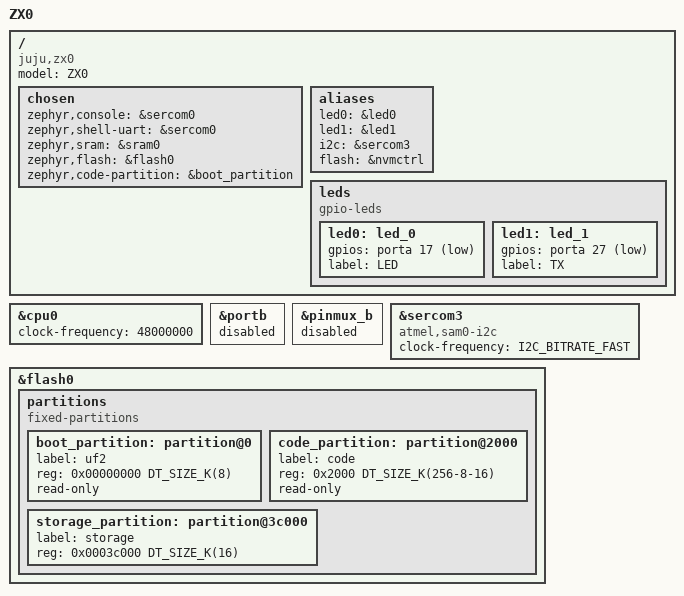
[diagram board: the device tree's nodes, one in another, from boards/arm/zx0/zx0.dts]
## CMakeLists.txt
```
cmake_minimum_required(VERSION 3.13.1)

list(APPEND BOARD_ROOT ${CMAKE_CURRENT_SOURCE_DIR})
set(BOARD zx0)

find_package(Zephyr REQUIRED HINTS $ENV{ZEPHYR_BASE})
project(zx0-boot)

target_sources(app PRIVATE src/main.cpp)
```

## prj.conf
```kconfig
# Drivers and peripherals
CONFIG_I2C=n
CONFIG_WATCHDOG=n
CONFIG_GPIO=y
CONFIG_PINMUX=y
CONFIG_SPI=n
CONFIG_SERIAL=n
CONFIG_FLASH=y
CONFIG_SAM0_EIC=n
CONFIG_SOC_FLASH_SAM0=y

# Power management
CONFIG_PM=n

# Interrupts
CONFIG_DYNAMIC_INTERRUPTS=n
CONFIG_IRQ_OFFLOAD=n

# Memory protection
CONFIG_THREAD_STACK_INFO=n
CONFIG_THREAD_CUSTOM_DATA=n
CONFIG_FPU=n

# Boot
CONFIG_BOOT_BANNER=n
CONFIG_BOOT_DELAY=0

# Console
CONFIG_CONSOLE=n
CONFIG_UART_CONSOLE=n
CONFIG_STDOUT_CONSOLE=n
CONFIG_PRINTK=n
CONFIG_EARLY_CONSOLE=n

# Build
CONFIG_SIZE_OPTIMIZATIONS=y

CONFIG_MULTITHREADING=n
CONFIG_KERNEL_MEM_POOL=n
CONFIG_SYS_CLOCK_EXISTS=n

CONFIG_BUILD_OUTPUT_HEX=y
#CONFIG_NEWLIB_LIBC=
CONFIG_CPLUSPLUS=y
CONFIG_STD_CPP2A=y
```

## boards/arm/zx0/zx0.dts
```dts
/*
 * Copyright (c) 2017 Google LLC.
 *
 * SPDX-License-Identifier: Apache-2.0
 */

/dts-v1/;
#include <atmel/samd21.dtsi>

/ {
	model = "ZX0";
	compatible = "juju,zx0", "atmel,samd21e18a", "atmel,samd21";

	chosen {
		zephyr,console = &sercom0;
		zephyr,shell-uart = &sercom0;
		zephyr,sram = &sram0;
		zephyr,flash = &flash0;
		zephyr,code-partition = &boot_partition;
	};

	/* These aliases are provided for compatibility with samples */
	aliases {
		led0 = &led0;
		led1 = &led1;
		i2c = &sercom3;
		flash = &nvmctrl;
	};

	leds {
		compatible = "gpio-leds";
		led0: led_0 {
			gpios = <&porta 17 GPIO_ACTIVE_LOW>;
			label = "LED";
		};
		led1: led_1 {
			gpios = <&porta 27 GPIO_ACTIVE_LOW>;
			label = "TX";
		};
	};

};

&cpu0 {
	clock-frequency = <48000000>;
};

&portb {
	status = "disabled";
};

&pinmux_b {
	status = "disabled";
};

&sercom3 {
	status = "okay";
	compatible = "atmel,sam0-i2c";
	clock-frequency = <I2C_BITRATE_FAST>;
	#address-cells = <1>;
	#size-cells = <0>;
};

&flash0 {
	partitions {
		compatible = "fixed-partitions";
		#address-cells = <1>;
		#size-cells = <1>;

		boot_partition: partition@0 {
			label = "uf2";
			reg = <0x00000000 DT_SIZE_K(8)>;
			read-only;
		};

		code_partition: partition@2000 {
			label = "code";
			reg = <0x2000 DT_SIZE_K(256-8-16)>;
			read-only;
		};

		/*
		 * The final 16 KiB is reserved for the application.
		 * Storage partition will be used by FCB/LittleFS/NVS
		 * if enabled.
		 */
		storage_partition: partition@3c000 {
			label = "storage";
			reg = <0x0003c000 DT_SIZE_K(16)>;
		};
	};
};
```

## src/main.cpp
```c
/*
 * Copyright (c) 2016 Intel Corporation
 *
 * SPDX-License-Identifier: Apache-2.0
 */

#include <device.h>
#include <devicetree.h>
#include <drivers/flash.h>
#include <drivers/gpio.h>
#include <drivers/pinmux.h>
#include <soc.h>
#include <string.h>
#include <sys/crc.h>
#include <zephyr.h>

#define LED0_NODE DT_ALIAS(led0)
#define LED1_NODE DT_ALIAS(led1)

static const struct gpio_dt_spec led0 = GPIO_DT_SPEC_GET_OR(LED0_NODE, gpios, {0});
static const struct gpio_dt_spec led1 = GPIO_DT_SPEC_GET_OR(LED1_NODE, gpios, {0});

static constexpr uint8_t kCommand = 0xFE;
static constexpr int kPageSize = NVMCTRL_ROW_SIZE;

class I2C {
   public:
    I2C(SercomI2cs *regs) : regs_(regs) {}
    void init();

    void poll();

    void received(const uint8_t *in, uint8_t *out);

   private:
    SercomI2cs *regs_;

    uint8_t input_buf_[64];
    uint8_t output_buf_[64];

    bool have_command_ = false;
    bool read_;
    uint8_t at_;
    bool ok_;
};

void I2C::init() {
    GCLK->CLKCTRL.reg = GCLK_CLKCTRL_ID_SERCOM3_CORE | GCLK_CLKCTRL_CLKEN | GCLK_CLKCTRL_GEN_GCLK0;
    PM->APBCMASK.bit.SERCOM3_ = 1;

    regs_->CTRLA.bit.SWRST = 1;
    while (regs_->SYNCBUSY.reg) {
    }

    regs_->CTRLA.reg = SERCOM_I2CS_CTRLA_MODE_I2C_SLAVE;
    regs_->CTRLB.reg = SERCOM_I2CS_CTRLB_SMEN;
    regs_->ADDR.reg = SERCOM_I2CS_ADDR_ADDR(0x22);

    while (regs_->SYNCBUSY.reg) {
    }
    regs_->CTRLA.bit.ENABLE = 1;
}

void I2C::poll() {
    uint32_t flags = regs_->INTFLAG.reg;

    if (flags & SERCOM_I2CS_INTFLAG_PREC) {
        regs_->INTFLAG.reg = SERCOM_I2CS_INTFLAG_PREC;
        // STOP received.
        if (!read_) {
            received(input_buf_, output_buf_);
        }
        have_command_ = false;
    }
    if (flags & SERCOM_I2CS_INTFLAG_AMATCH) {
        regs_->INTFLAG.reg = SERCOM_I2CS_INTFLAG_AMATCH;
        at_ = 0;
        read_ = regs_->STATUS.bit.DIR;
    }
    if (flags & SERCOM_I2CS_INTFLAG_DRDY) {
        // Flag is cleared by hardware when DATA is read or written.
        if (!read_) {
            uint8_t data = regs_->DATA.reg;
            if (!have_command_) {
                if (data == kCommand) {
                    have_command_ = true;
                    ok_ = true;
                }
            } else if (have_command_ && at_ < sizeof(input_buf_)) {
                input_buf_[at_++] = data;
            } else {
                // Overflow or bad command, discard.
            }
        } else {
            if (have_command_ && at_ < sizeof(output_buf_)) {
                regs_->DATA.reg = output_buf_[at_++];
            } else {
                regs_->DATA.reg = 0;
            }
        }
    }
}

struct WriteFlashPage {
    uint32_t target_addr;
    uint8_t data[0];
};

struct ChksumPages {
    uint32_t target_addr;
    uint32_t num_pages;
};

struct Command {
    enum class ID : uint32_t {
        BININFO = 1,
        INFO = 2,
        RESET_INTO_APP = 3,
        RESET_INTO_BOOTLOADER = 4,
        START_FLASH = 5,
        WRITE_FLASH_PAGE = 6,
        CHKSUM_PAGES = 7,
    };

    ID command_id;
    uint16_t tag;
    uint8_t reserved0;
    uint8_t reserved1;

    union {
        WriteFlashPage write_flash_page;
        ChksumPages chksum_pages;
    };
};

struct Header {
    enum class Status : uint8_t {
        OK,
        Invalid,
        Error,
    };

    uint16_t tag;
    Status status;
    uint8_t status_info;
};

struct BinInfo {
    enum class Mode : uint32_t {
        Bootloader = 1,
        UserSpace = 2,
    };

    Mode mode;
    uint32_t flash_page_size;
    uint32_t flash_num_pages;
    uint32_t max_message_size;
    uint32_t family_id;
};

struct Response {
    Header header;

    union {
        BinInfo bininfo;
        uint16_t chksums[16];
    };
};

class HF2 {
   public:
    void init(const device *flash) { flash_ = flash; }

    void packet(const uint8_t *in, uint8_t *out);

   private:
    enum {
        Inner = 0x00,
        Final = 0x40,
        StdinStderr = 0x80,
        TypeMask = 0xC0,
        SizeMask = 63,
    };

    size_t message(Command &command, Response &resp);

    size_t bininfo(BinInfo &resp);
    size_t chksum_pages(uint32_t addr, uint32_t pages, uint16_t *chksums);
    size_t write_flash_page(uint32_t addr, const uint8_t *data);
    size_t reset_into_app();

    uint8_t message_[kPageSize * 3 / 2];
    uint16_t at_ = 0;
    const device *flash_;
};

#define APP_START_ADDRESS 0x2000

void HF2::packet(const uint8_t *in, uint8_t *out) {
    uint8_t header = in[0];
    if ((header & StdinStderr) != 0) {
        return;
    }

    auto size = header & SizeMask;
    size_t end = at_ + size;
    if (end >= sizeof(message_)) {
        return;
    }

    memcpy(message_ + at_, in + 1, size);
    at_ += size;

    if ((header & Final) == 0) {
        return;
    }

    at_ = 0;

    Response resp;
    auto wrote = message(*(Command *)message_, resp);
    memcpy(out + 2, &resp, wrote);
    out[0] = wrote + 1;
    out[1] = wrote | Final;
}

size_t HF2::bininfo(BinInfo &resp) {
    resp = {
        .mode = BinInfo::Mode::Bootloader,
        .flash_page_size = kPageSize,
        .flash_num_pages = 1024,
        .max_message_size = sizeof(message_),
        .family_id = 1234,
    };
    return sizeof(BinInfo);
}

size_t HF2::chksum_pages(uint32_t addr, uint32_t pages, uint16_t *chksums) {
    for (uint32_t i = 0; i < pages; i++) {
        chksums[i] = crc16_itu_t(0, (uint8_t *)addr + i * kPageSize, kPageSize);
    }
    return pages * sizeof(*chksums);
}

size_t HF2::write_flash_page(uint32_t addr, const uint8_t *data) {
    int err = flash_erase(flash_, addr, kPageSize);
    if (err != 0) {
        return err;
    }
    return flash_write(flash_, addr, data, kPageSize);
}

static int enter_app() {
    /* Load the Reset Handler address of the application */
    uint32_t app_start_address = *(uint32_t *)(APP_START_ADDRESS + 4);

    /**
     * Test reset vector of application @APP_START_ADDRESS+4
     * Sanity check on the Reset_Handler address
     */
    if (app_start_address < APP_START_ADDRESS || app_start_address > FLASH_SIZE) {
        /* Stay in bootloader */
        return -ENOENT;
    }

    /* Rebase the Stack Pointer */
    __set_MSP(*(uint32_t *)APP_START_ADDRESS);

    /* Rebase the vector table base address */
    SCB->VTOR = ((uint32_t)APP_START_ADDRESS & SCB_VTOR_TBLOFF_Msk);

    /* Jump to application Reset Handler in the application */
    asm("bx %0" ::"r"(app_start_address));

    return 0;
}

size_t HF2::reset_into_app() { return enter_app(); }

size_t HF2::message(Command &command, Response &resp) {
    gpio_pin_toggle(led1.port, led1.pin);

    int err = -EINVAL;

    switch (command.command_id) {
        case Command::ID::BININFO:
            err = bininfo(resp.bininfo);
            break;
        case Command::ID::WRITE_FLASH_PAGE:
            err = write_flash_page(command.write_flash_page.target_addr,
                                   command.write_flash_page.data);
            break;
        case Command::ID::CHKSUM_PAGES:
            err = chksum_pages(command.chksum_pages.target_addr, command.chksum_pages.num_pages,
                               resp.chksums);
            break;
        case Command::ID::RESET_INTO_APP:
            err = reset_into_app();
            break;
        default:
            break;
    }

    if (err < 0) {
        resp.header = {
            .tag = command.tag,
            .status = Header::Status::Error,
            .status_info = -err,
        };
        return sizeof(Header);
    }

    resp.header = {
        .tag = command.tag,
        .status = Header::Status::OK,
        .status_info = 0,
    };
    return sizeof(Header) + err;
}

static I2C i2c((SercomI2cs *)DT_REG_ADDR_BY_IDX(DT_ALIAS(i2c), 0));
static HF2 hf2;

void I2C::received(const uint8_t *in, uint8_t *out) { hf2.packet(in, out); }

void main(void) {
    gpio_pin_configure_dt(&led0, GPIO_OUTPUT_INACTIVE);
    gpio_pin_configure_dt(&led1, GPIO_OUTPUT_INACTIVE);

    auto flash = DEVICE_DT_GET(DT_ALIAS(flash));

    hf2.init(flash);
    i2c.init();

    //   enter_app();

    for (;;) {
        gpio_pin_toggle(led0.port, led0.pin);
        for (int spin = 0; spin < 200000; spin++) {
            i2c.poll();
        }
    }
}
```

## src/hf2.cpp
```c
#include "hf2.h"

#include <drivers/flash.h>
#include <drivers/gpio.h>
#include <string.h>
#include <sys/crc.h>

void HF2::packet(const uint8_t *in, uint8_t *out) {
    uint8_t header = in[0];
    if ((header & StdinStderr) != 0) {
        return;
    }

    auto size = header & SizeMask;
    size_t end = at_ + size;
    if (end >= sizeof(message_)) {
        return;
    }

    memcpy(message_ + at_, in + 1, size);
    at_ += size;

    if ((header & Final) == 0) {
        return;
    }

    at_ = 0;

    Response resp;
    auto wrote = message(*(Command *)message_, resp);
    memcpy(out + 2, &resp, wrote);
    out[0] = wrote + 1;
    out[1] = wrote | Final;
}

size_t HF2::bininfo(BinInfo &resp) {
    resp = {
        .mode = BinInfo::Mode::Bootloader,
        .flash_page_size = HAL::kPageSize,
        .flash_num_pages = HAL::kNumPages,
        .max_message_size = sizeof(message_),
        .family_id = 1234,
    };
    return sizeof(BinInfo);
}

size_t HF2::chksum_pages(uint32_t addr, uint32_t pages, uint16_t *chksums) {
    for (uint32_t i = 0; i < pages; i++) {
        chksums[i] = crc16_itu_t(0, (uint8_t *)addr + i * HAL::kPageSize, HAL::kPageSize);
    }
    return pages * sizeof(*chksums);
}

size_t HF2::write_flash_page(uint32_t addr, const uint8_t *data) {
    int err = flash_erase(flash_, addr, HAL::kPageSize);
    if (err != 0) {
        return err;
    }
    return flash_write(flash_, addr, data, HAL::kPageSize);
}

size_t HF2::reset_into_app() { return HAL::enter_app(); }

size_t HF2::message(Command &command, Response &resp) {
    gpio_pin_toggle(HAL::led1.port, HAL::led1.pin);

    int err = -EINVAL;

    switch (command.command_id) {
        case Command::ID::BININFO:
            err = bininfo(resp.bininfo);
            break;
        case Command::ID::WRITE_FLASH_PAGE:
            err = write_flash_page(command.write_flash_page.target_addr,
                                   command.write_flash_page.data);
            break;
        case Command::ID::CHKSUM_PAGES:
            err = chksum_pages(command.chksum_pages.target_addr, command.chksum_pages.num_pages,
                               resp.chksums);
            break;
        case Command::ID::RESET_INTO_APP:
            err = reset_into_app();
            break;
        default:
            break;
    }

    if (err < 0) {
        resp.header = {
            .tag = command.tag,
            .status = Header::Status::Error,
            .status_info = static_cast<uint8_t>(-err),
        };
        return sizeof(Header);
    }

    resp.header = {
        .tag = command.tag,
        .status = Header::Status::OK,
        .status_info = 0,
    };
    return sizeof(Header) + err;
}
```

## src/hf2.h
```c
#pragma once

#include <device.h>

#include "hal.h"

struct Command;
struct Response;
struct BinInfo;

class HF2 {
   public:
    HF2(const device *flash) : flash_(flash) {}

    void packet(const uint8_t *in, uint8_t *out);

   private:
    enum Flag {
        Inner = 0x00,
        Final = 0x40,
        StdinStderr = 0x80,
        TypeMask = 0xC0,
        SizeMask = 63,
    };

    size_t message(Command &command, Response &resp);

    size_t bininfo(BinInfo &resp);
    size_t chksum_pages(uint32_t addr, uint32_t pages, uint16_t *chksums);
    size_t write_flash_page(uint32_t addr, const uint8_t *data);
    size_t reset_into_app();
    size_t read_words(uint32_t addr, uint32_t count, uint32_t *words);

    uint8_t message_[HAL::kPageSize * 3 / 2];
    uint16_t at_ = 0;
    const device *flash_;
};
```

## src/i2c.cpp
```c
#include "i2c.h"

static constexpr uint8_t kCommand = 0xFE;

void I2C::init() {
    GCLK->CLKCTRL.reg = GCLK_CLKCTRL_ID_SERCOM3_CORE | GCLK_CLKCTRL_CLKEN | GCLK_CLKCTRL_GEN_GCLK0;
    PM->APBCMASK.bit.SERCOM3_ = 1;

    regs_->CTRLA.bit.SWRST = 1;
    while (regs_->SYNCBUSY.reg) {
    }

    regs_->CTRLA.reg = SERCOM_I2CS_CTRLA_MODE_I2C_SLAVE;
    regs_->CTRLB.reg = SERCOM_I2CS_CTRLB_SMEN;
    regs_->ADDR.reg = SERCOM_I2CS_ADDR_ADDR(0x22);

    while (regs_->SYNCBUSY.reg) {
    }
    regs_->CTRLA.bit.ENABLE = 1;
}

void I2C::poll() {
    uint32_t flags = regs_->INTFLAG.reg;

    if (flags & SERCOM_I2CS_INTFLAG_PREC) {
        regs_->INTFLAG.reg = SERCOM_I2CS_INTFLAG_PREC;
        // STOP received.
        if (!read_) {
            received(input_buf_, output_buf_);
        }
        have_command_ = false;
    }
    if (flags & SERCOM_I2CS_INTFLAG_AMATCH) {
        regs_->INTFLAG.reg = SERCOM_I2CS_INTFLAG_AMATCH;
        at_ = 0;
        read_ = regs_->STATUS.bit.DIR;
    }
    if (flags & SERCOM_I2CS_INTFLAG_DRDY) {
        // Flag is cleared by hardware when DATA is read or written.
        if (!read_) {
            uint8_t data = regs_->DATA.reg;
            if (!have_command_) {
                if (data == kCommand) {
                    have_command_ = true;
                    ok_ = true;
                }
            } else if (have_command_ && at_ < sizeof(input_buf_)) {
                input_buf_[at_++] = data;
            } else {
                // Overflow or bad command, discard.
            }
        } else {
            if (have_command_ && at_ < sizeof(output_buf_)) {
                regs_->DATA.reg = output_buf_[at_++];
            } else {
                regs_->DATA.reg = 0;
            }
        }
    }
}
```

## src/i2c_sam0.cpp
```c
#include "i2c_sam0.h"

static constexpr uint8_t kCommand = 0xFE;

void I2C::init() {
    GCLK->CLKCTRL.reg = GCLK_CLKCTRL_ID_SERCOM3_CORE | GCLK_CLKCTRL_CLKEN | GCLK_CLKCTRL_GEN_GCLK0;
    PM->APBCMASK.bit.SERCOM3_ = 1;

    regs_->CTRLA.bit.SWRST = 1;
    while (regs_->SYNCBUSY.reg) {
    }

    regs_->CTRLA.reg = SERCOM_I2CS_CTRLA_MODE_I2C_SLAVE;
    regs_->CTRLB.reg = SERCOM_I2CS_CTRLB_SMEN;
    regs_->ADDR.reg = SERCOM_I2CS_ADDR_ADDR(0x22);

    while (regs_->SYNCBUSY.reg) {
    }
    regs_->CTRLA.bit.ENABLE = 1;
}

void I2C::poll() {
    uint32_t flags = regs_->INTFLAG.reg;

    if (flags & SERCOM_I2CS_INTFLAG_PREC) {
        regs_->INTFLAG.reg = SERCOM_I2CS_INTFLAG_PREC;
        // STOP received.
        if (!read_) {
            received(input_buf_, output_buf_);
        }
        have_command_ = false;
    }
    if (flags & SERCOM_I2CS_INTFLAG_AMATCH) {
        regs_->INTFLAG.reg = SERCOM_I2CS_INTFLAG_AMATCH;
        at_ = 0;
        read_ = regs_->STATUS.bit.DIR;
    }
    if (flags & SERCOM_I2CS_INTFLAG_DRDY) {
        // Flag is cleared by hardware when DATA is read or written.
        if (!read_) {
            uint8_t data = regs_->DATA.reg;
            if (!have_command_) {
                if (data == kCommand) {
                    have_command_ = true;
                    ok_ = true;
                }
            } else if (have_command_ && at_ < sizeof(input_buf_)) {
                input_buf_[at_++] = data;
            } else {
                // Overflow or bad command, discard.
            }
        } else {
            if (have_command_ && at_ < sizeof(output_buf_)) {
                regs_->DATA.reg = output_buf_[at_++];
            } else {
                regs_->DATA.reg = 0;
            }
        }
    }
}
```
